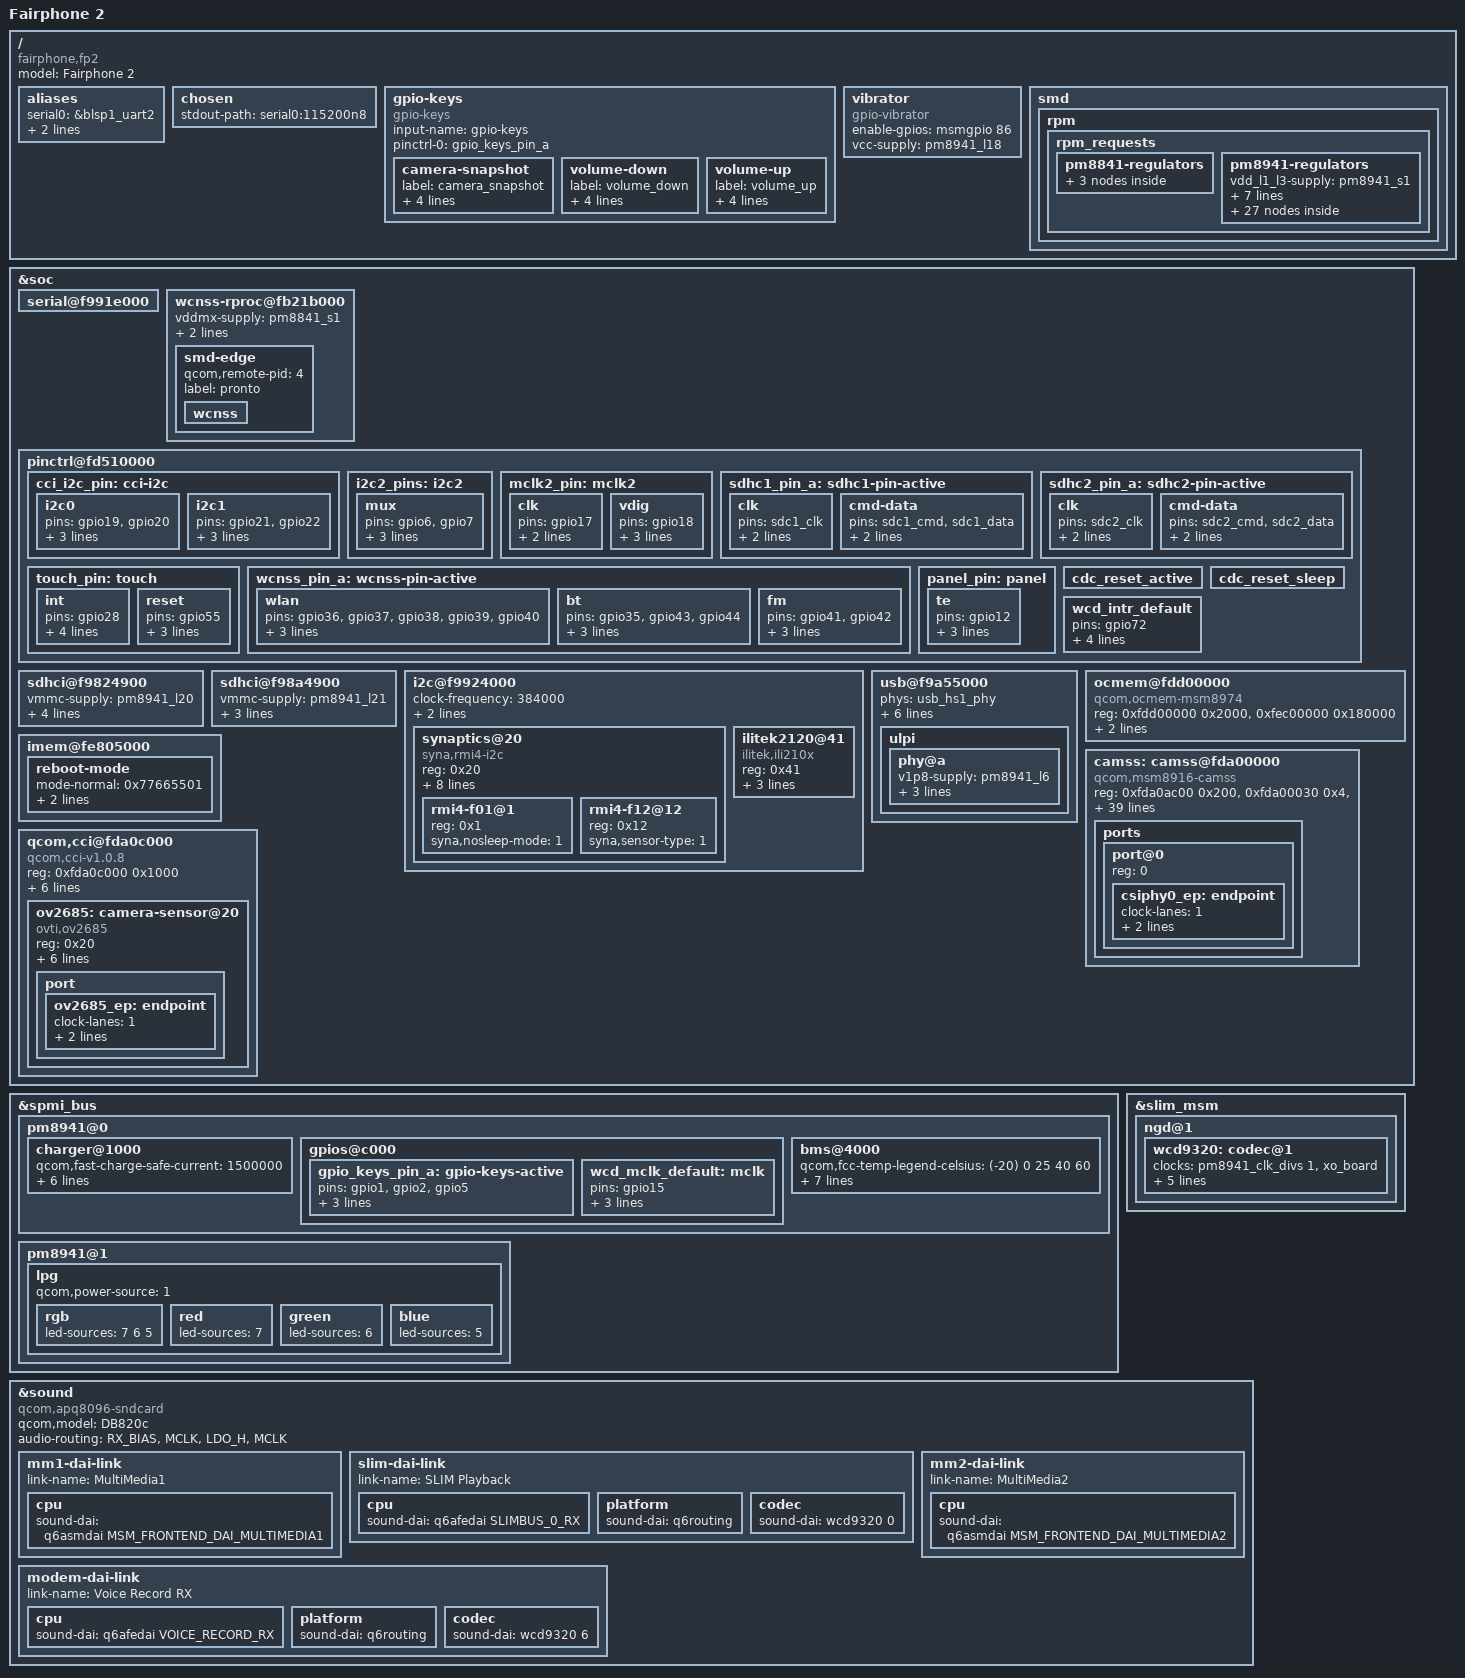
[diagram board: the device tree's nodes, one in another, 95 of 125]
#include "qcom-msm8974pro.dtsi"
#include "qcom-pm8841.dtsi"
#include "qcom-pm8941.dtsi"
#include <dt-bindings/gpio/gpio.h>
#include <dt-bindings/input/input.h>
#include <dt-bindings/pinctrl/qcom,pmic-gpio.h>
#include <dt-bindings/clock/qcom,mmcc-msm8974.h>


/ {
	model = "Fairphone 2";
	compatible = "fairphone,fp2", "qcom,msm8974";

	aliases {
		serial0 = &blsp1_uart2;
		mmc0 = &sdhc_1;
		mmc1 = &sdhc_3;
	};

	chosen {
		stdout-path = "serial0:115200n8";
	};

	gpio-keys {
		compatible = "gpio-keys";
		input-name = "gpio-keys";

		pinctrl-names = "default";
		pinctrl-0 = <&gpio_keys_pin_a>;

		camera-snapshot {
			label = "camera_snapshot";
			gpios = <&pm8941_gpios 1 GPIO_ACTIVE_LOW>;
			linux,code = <KEY_CAMERA>;
			wakeup-source;
			debounce-interval = <15>;
		};

		volume-down {
			label = "volume_down";
			gpios = <&pm8941_gpios 2 GPIO_ACTIVE_LOW>;
			linux,code = <KEY_VOLUMEDOWN>;
			wakeup-source;
			debounce-interval = <15>;
		};

		volume-up {
			label = "volume_up";
			gpios = <&pm8941_gpios 5 GPIO_ACTIVE_LOW>;
			linux,code = <KEY_VOLUMEUP>;
			wakeup-source;
			debounce-interval = <15>;
		};
	};

	vibrator {
		compatible = "gpio-vibrator";
		enable-gpios = <&msmgpio 86 GPIO_ACTIVE_HIGH>;
		vcc-supply = <&pm8941_l18>;
	};

	smd {
		rpm {
			rpm_requests {
				pm8841-regulators {
					s1 {
						regulator-min-microvolt = <675000>;
						regulator-max-microvolt = <1050000>;
					};

					s2 {
						regulator-min-microvolt = <500000>;
						regulator-max-microvolt = <1050000>;
					};

					s3 {
						regulator-min-microvolt = <1050000>;
						regulator-max-microvolt = <1050000>;
					};
				};

				pm8941-regulators {
					vdd_l1_l3-supply = <&pm8941_s1>;
					vdd_l2_lvs1_2_3-supply = <&pm8941_s3>;
					vdd_l4_l11-supply = <&pm8941_s1>;
					vdd_l5_l7-supply = <&pm8941_s2>;
					vdd_l6_l12_l14_l15-supply = <&pm8941_s2>;
					vdd_l9_l10_l17_l22-supply = <&vreg_boost>;
					vdd_l13_l20_l23_l24-supply = <&vreg_boost>;
					vdd_l21-supply = <&vreg_boost>;

					s1 {
						regulator-min-microvolt = <1300000>;
						regulator-max-microvolt = <1300000>;

						regulator-always-on;
						regulator-boot-on;
					};

					s2 {
						regulator-min-microvolt = <2150000>;
						regulator-max-microvolt = <2150000>;

						regulator-boot-on;
					};

					s3 {
						regulator-min-microvolt = <1800000>;
						regulator-max-microvolt = <1800000>;

						regulator-always-on;
						regulator-boot-on;
					};

					l1 {
						regulator-min-microvolt = <1225000>;
						regulator-max-microvolt = <1225000>;

						regulator-always-on;
						regulator-boot-on;
					};

					l2 {
						regulator-min-microvolt = <1200000>;
						regulator-max-microvolt = <1200000>;
					};

					l3 {
						regulator-min-microvolt = <1225000>;
						regulator-max-microvolt = <1225000>;
					};

					l4 {
						regulator-min-microvolt = <1225000>;
						regulator-max-microvolt = <1225000>;
					};

					l5 {
						regulator-min-microvolt = <1800000>;
						regulator-max-microvolt = <1800000>;
					};

					l6 {
						regulator-min-microvolt = <1800000>;
						regulator-max-microvolt = <1800000>;

						regulator-boot-on;
					};

					l7 {
						regulator-min-microvolt = <1800000>;
						regulator-max-microvolt = <1800000>;

						regulator-boot-on;
					};

					l8 {
						regulator-min-microvolt = <1800000>;
						regulator-max-microvolt = <1800000>;
					};

					l9 {
						regulator-min-microvolt = <1800000>;
						regulator-max-microvolt = <2950000>;
					};

					l10 {
						regulator-min-microvolt = <1800000>;
						regulator-max-microvolt = <2950000>;
					};

					l11 {
						regulator-min-microvolt = <1225000>;
						regulator-max-microvolt = <1350000>;
					};

					l12 {
						regulator-min-microvolt = <1800000>;
						regulator-max-microvolt = <1800000>;

						regulator-always-on;
						regulator-boot-on;
					};

					l13 {
						regulator-min-microvolt = <1800000>;
						regulator-max-microvolt = <2950000>;

						regulator-boot-on;
					};

					l14 {
						regulator-min-microvolt = <1800000>;
						regulator-max-microvolt = <1800000>;
					};

					l15 {
						regulator-min-microvolt = <2050000>;
						regulator-max-microvolt = <2050000>;
					};

					l16 {
						regulator-min-microvolt = <2700000>;
						regulator-max-microvolt = <2700000>;
					};

					l17 {
						regulator-min-microvolt = <2850000>;
						regulator-max-microvolt = <2850000>;
					};

					l18 {
						regulator-min-microvolt = <2850000>;
						regulator-max-microvolt = <2850000>;
					};

					l19 {
						regulator-min-microvolt = <2900000>;
						regulator-max-microvolt = <3350000>;
					};

					l20 {
						regulator-min-microvolt = <2950000>;
						regulator-max-microvolt = <2950000>;

						regulator-boot-on;
						regulator-system-load = <200000>;
						regulator-allow-set-load;
					};

					l21 {
						regulator-min-microvolt = <2950000>;
						regulator-max-microvolt = <2950000>;

						regulator-boot-on;
					};

					l22 {
						regulator-min-microvolt = <3000000>;
						regulator-max-microvolt = <3300000>;
					};

					l23 {
						regulator-min-microvolt = <3000000>;
						regulator-max-microvolt = <3000000>;
					};

					l24 {
						regulator-min-microvolt = <3075000>;
						regulator-max-microvolt = <3075000>;

						regulator-boot-on;
					};
				};
			};
		};
	};
};

&soc {
	serial@f991e000 {
		status = "ok";
	};

	wcnss-rproc@fb21b000 {
		status = "ok";

		vddmx-supply = <&pm8841_s1>;
		vddcx-supply = <&pm8841_s2>;

		pinctrl-names = "default";
		pinctrl-0 = <&wcnss_pin_a>;

		smd-edge {
			qcom,remote-pid = <4>;
			label = "pronto";

			wcnss {
				status = "ok";
			};
		};
	};

	pinctrl@fd510000 {
		cci_i2c_pin: cci-i2c {
			i2c0 {
				pins = "gpio19", "gpio20";
				function = "cci_i2c0";

				drive-strength = <2>;
				bias-disable;
			};
			i2c1 {
				pins = "gpio21", "gpio22";
				function = "cci_i2c1";

				drive-strength = <2>;
				bias-disable;
			};
		};

		i2c2_pins: i2c2 {
			mux {
				pins = "gpio6", "gpio7";
				function = "blsp_i2c2";

				drive-strength = <2>;
				bias-disable;
			};
		};

/*
		mclk0_pin: mclk0 {
			clk {
				pins = "gpio15";
				function = "cam_mclk0";
				bias-disable;
				//output-high;
			};
		};
*/

		mclk2_pin: mclk2 {
			clk {
				pins = "gpio17";
				function = "cam_mclk2";
				bias-disable;
			};
			vdig { // FIXME name is weird, v-digital? or reset pin?
				pins = "gpio18";
				function = "gpio";
				drive-strength = <2>;
				bias-disable;
			};
		};

		sdhc1_pin_a: sdhc1-pin-active {
			clk {
				pins = "sdc1_clk";
				drive-strength = <16>;
				bias-disable;
			};

			cmd-data {
				pins = "sdc1_cmd", "sdc1_data";
				drive-strength = <10>;
				bias-pull-up;
			};
		};

		sdhc2_pin_a: sdhc2-pin-active {
			clk {
				pins = "sdc2_clk";
				drive-strength = <10>;
				bias-disable;
			};

			cmd-data {
				pins = "sdc2_cmd", "sdc2_data";
				drive-strength = <6>;
				bias-pull-up;
			};
		};

		touch_pin: touch {
			int {
				pins = "gpio28";
				function = "gpio";

				drive-strength = <2>;
				bias-disable;
				input-enable;
			};

			reset {
				pins = "gpio55";
				function = "gpio";

				drive-strength = <2>;
				bias-pull-up;
			};
		};

		wcnss_pin_a: wcnss-pin-active {
			wlan {
				pins =  "gpio36", "gpio37", "gpio38", "gpio39", "gpio40";
				function = "wlan";

				drive-strength = <6>;
				bias-pull-down;
			};

			bt {
				pins = "gpio35", "gpio43", "gpio44";
				function = "bt";

				drive-strength = <2>;
				bias-pull-down;
			};

			fm {
				pins = "gpio41", "gpio42";
				function = "fm";

				drive-strength = <2>;
				bias-pull-down;
			};
		};

		panel_pin: panel {
			te {
				pins = "gpio12";
				function = "mdp_vsync";

				drive-strength = <2>;
				bias-disable;
			};
		};

		cdc_reset_active: cdc_reset_active {

		};

		cdc_reset_sleep: cdc_reset_sleep {

		};

		wcd_intr_default: wcd_intr_default {
			pins = "gpio72";
			function = "gpio";
			drive-strength = <2>;
			bias-disable;
			input-enable;
		};
	};

	sdhci@f9824900 {
		status = "ok";

		vmmc-supply = <&pm8941_l20>;
		vqmmc-supply = <&pm8941_s3>;

		bus-width = <8>;
		non-removable;

		pinctrl-names = "default";
		pinctrl-0 = <&sdhc1_pin_a>;
	};

	sdhci@f98a4900 {
		status = "ok";

		vmmc-supply = <&pm8941_l21>;
		vqmmc-supply = <&pm8941_l13>;

		bus-width = <4>;

		pinctrl-names = "default";
		pinctrl-0 = <&sdhc2_pin_a>;
	};


	i2c@f9924000 {
		status = "ok";

		clock-frequency = <384000>;
		qcom,src-freq = <19200000>;

		pinctrl-names = "default";
		pinctrl-0 = <&i2c2_pins>;

		synaptics@20 {
			compatible = "syna,rmi4-i2c";
			reg = <0x20>;

			interrupts-extended = <&msmgpio 28 IRQ_TYPE_LEVEL_LOW>;

			#address-cells = <1>;
			#size-cells = <0>;

			vdd-supply = <&pm8941_l22>;
			vio-supply = <&pm8941_s3>;

			pinctrl-names = "default";
			pinctrl-0 = <&touch_pin>;

			syna,nosleep-mode = <2>;
			syna,startup-delay-ms = <160>;
			syna,reset-delay-ms = <100>;

			rmi4-f01@1 {
				reg = <0x1>;
				syna,nosleep-mode = <1>;
			};

			rmi4-f12@12 {
				reg = <0x12>;
				syna,sensor-type = <1>;
			};
		};

		ilitek2120@41 {
			compatible = "ilitek,ili210x";
			reg = <0x41>;
			interrupt-parent = <&msmgpio>;
			interrupts = <28 IRQ_TYPE_EDGE_FALLING>;
			reset-gpios = <&msmgpio 55 GPIO_ACTIVE_LOW>;
		};
	};

	usb@f9a55000 {
		status = "ok";

		phys = <&usb_hs1_phy>;
		phy-select = <&tcsr 0xb000 0>;
		extcon = <&smbb>, <&usb_id>;
		vbus-supply = <&chg_otg>;

		hnp-disable;
		srp-disable;
		adp-disable;

		ulpi {
			phy@a {
				status = "ok";

				v1p8-supply = <&pm8941_l6>;
				v3p3-supply = <&pm8941_l24>;

				extcon = <&smbb>;
				qcom,init-seq = /bits/ 8 <0x1 0x64>;
			};
		};
	};

	ocmem@fdd00000 {
		compatible = "qcom,ocmem-msm8974";
		// "ocmem_ctrl_physical" should be the registers, "ocmem_physical"
		// is (I think) letting CPU read ocmem directly..

		reg = <0xfdd00000 0x2000>,
			<0xfec00000 0x180000>;
		reg-names = "ocmem_ctrl_physical",
			"ocmem_physical";

		clocks = <&rpmcc RPM_SMD_OCMEMGX_CLK>,
			<&mmcc OCMEMCX_OCMEMNOC_CLK>;
		clock-names = "core_clk", "iface_clk";
	};

	/*mdss@fd900000 {
		status = "ok";

		mdp@fd900000 {
			status = "ok";
		};

		dsi@fd922800 {
			status = "ok";

			vdda-supply = <&pm8941_l2>;
			vdd-supply = <&pm8941_l22>;
			vddio-supply = <&pm8941_l12>;

			#address-cells = <1>;
			#size-cells = <0>;

			ports {
				port@1 {
					endpoint {
						remote-endpoint = <&panel_in>;
						data-lanes = <0 1 2 3>;
					};
				};
			};

			panel: panel@0 {
				reg = <0>;
				compatible = "something,s6d6fa1";

				pinctrl-names = "default";
				pinctrl-0 = <&panel_pin>;

				port {
					panel_in: endpoint {
						remote-endpoint = <&dsi0_out>;
					};
				};
			};
		};

		dsi-phy@fd922a00 {
			status = "ok";

			vddio-supply = <&pm8941_l12>;
		};
	};*/

	imem@fe805000 {
		status = "okay";

		reboot-mode {
			mode-normal	= <0x77665501>;
			mode-bootloader	= <0x77665500>;
			mode-recovery	= <0x77665502>;
		};
	};

	camss: camss@fda00000 {
		// missing cpp and cci blocks + msm-cam

		compatible = "qcom,msm8916-camss";
		reg = <0xfda0ac00 0x200>,
			<0xfda00030 0x4>,
			<0xfda0b000 0x200>,
			<0xfda00038 0x4>,
			<0xfda0b400 0x200>,
			<0xfda00040 0x4>,

			<0xfda08000 0x100>,
			<0xfda08400 0x100>,
			<0xfda08800 0x100>,
			<0xfda08c00 0x100>,

			<0xfda0a000 0x800>,
			<0xfda00020 0x10>,
			<0xfda10000 0x1000>,
			<0xfda14000 0x1000>;
		// 0xfda40000 0x200 : vfe_vbif
		reg-names = "csiphy0",
			"csiphy0_clk_mux",
			"csiphy1",
			"csiphy1_clk_mux",
			"csiphy2",
			"csiphy2_clk_mux",
			"csid0",
			"csid1",
			"csid2",
			"csid3",
			"ispif",
			"csi_clk_mux",
			"vfe0",
			"vfe1";
		interrupts = <GIC_SPI 78 0>,
			<GIC_SPI 79 0>,
			<GIC_SPI 80 0>,
			<GIC_SPI 51 0>,
			<GIC_SPI 52 0>,
			<GIC_SPI 53 0>,
			<GIC_SPI 54 0>,
			<GIC_SPI 55 0>,
			<GIC_SPI 57 0>,
			<GIC_SPI 58 0>;
		interrupt-names = "csiphy0",
			"csiphy1",
			"csiphy2",
			"csid0",
			"csid1",
			"csid2",
			"csid3",
			"ispif",
			"vfe0",
			"vfe1";
		power-domains = <&mmcc CAMSS_VFE_GDSC>;
		clocks = <&mmcc CAMSS_TOP_AHB_CLK>,
			<&mmcc CAMSS_ISPIF_AHB_CLK>,
			<&mmcc CAMSS_PHY0_CSI0PHYTIMER_CLK>,
			<&mmcc CAMSS_PHY1_CSI1PHYTIMER_CLK>,
			<&mmcc CAMSS_PHY2_CSI2PHYTIMER_CLK>,

			<&mmcc CAMSS_CSI0_AHB_CLK>, <&mmcc CAMSS_CSI0_CLK>, <&mmcc CAMSS_CSI0PHY_CLK>,
			<&mmcc CAMSS_CSI0PIX_CLK>, <&mmcc CAMSS_CSI0RDI_CLK>,
			<&mmcc CAMSS_CSI1_AHB_CLK>, <&mmcc CAMSS_CSI1_CLK>, <&mmcc CAMSS_CSI1PHY_CLK>,
			<&mmcc CAMSS_CSI1PIX_CLK>, <&mmcc CAMSS_CSI1RDI_CLK>,
			<&mmcc CAMSS_CSI2_AHB_CLK>, <&mmcc CAMSS_CSI2_CLK>, <&mmcc CAMSS_CSI2PHY_CLK>,
			<&mmcc CAMSS_CSI2PIX_CLK>, <&mmcc CAMSS_CSI2RDI_CLK>,
			<&mmcc CAMSS_CSI3_AHB_CLK>, <&mmcc CAMSS_CSI3_CLK>, <&mmcc CAMSS_CSI3PHY_CLK>,
			<&mmcc CAMSS_CSI3PIX_CLK>, <&mmcc CAMSS_CSI3RDI_CLK>,

			// <&gcc GCC_CAMSS_AHB_CLK>,

			<&mmcc CAMSS_VFE_VFE0_CLK>,
			<&mmcc CAMSS_VFE_VFE1_CLK>,
			<&mmcc CAMSS_CSI_VFE0_CLK>,
			<&mmcc CAMSS_CSI_VFE1_CLK>,
			<&mmcc CAMSS_VFE_VFE_AHB_CLK>,
			<&mmcc CAMSS_VFE_VFE_AXI_CLK>;
		// CAMSS_VFE_VFE_OCMEMNOC_CLK
                clock-names = "top_ahb",
                        "ispif_ahb",
                        "csiphy0_timer",
                        "csiphy1_timer",
                        "csiphy2_timer",
                        "csi0_ahb", "csi0", "csi0_phy", "csi0_pix", "csi0_rdi",
                        "csi1_ahb", "csi1", "csi1_phy", "csi1_pix", "csi1_rdi",
                        "csi2_ahb", "csi2", "csi2_phy", "csi2_pix", "csi2_rdi",
                        "csi3_ahb", "csi3", "csi3_phy", "csi3_pix", "csi3_rdi",
                        // "camss_ahb",
                        "vfe0",
                        "vfe1",
                        "csi_vfe0",
                        "csi_vfe1",
                        "iface",
                        "bus";
		vdda-supply = <&pm8941_l12>;
		// iommus = <...>;
		ports {
			#address-cells = <1>;
			#size-cells = <0>;
			port@0 {
				reg = <0>;
				csiphy0_ep: endpoint {
					clock-lanes = <1>;
					data-lanes = <0 2 3 4>;
					remote-endpoint = <&ov2685_ep>;
				};
			};
		};
	};

	qcom,cci@fda0c000 {
		compatible = "qcom,cci-v1.0.8";
		#address-cells = <1>;
		#size-cells = <0>;
		reg = <0xfda0c000 0x1000>;
		reg-names = "cci";
		interrupts = <GIC_SPI 50 IRQ_TYPE_EDGE_RISING>;
		interrupt-names = "cci";
		clocks = <&mmcc CAMSS_TOP_AHB_CLK>,
			<&mmcc CAMSS_CCI_CCI_AHB_CLK>,
			<&mmcc CAMSS_CCI_CCI_CLK>;
			// <&gcc GCC_CAMSS_AHB_CLK>;
		clock-names = "camss_top_ahb",
			"cci_ahb",
			"cci";
			// "camss_ahb";
		pinctrl-names = "default";
		pinctrl-0 = <&cci_i2c_pin>;

		clock-frequency = <400000>;

		ov2685: camera-sensor@20 {
			compatible = "ovti,ov2685";
			reg = <0x20>;

			clocks = <&mmcc CAMSS_MCLK2_CLK>;
			clock-names = "xvclk";

			avdd-supply = <&pm8941_l22>;
			dovdd-supply = <&pm8941_lvs3>;
			dvdd-supply = <&pm8941_l3>;
			reset-gpios = <&msmgpio 18 GPIO_ACTIVE_HIGH>;

			// Uses csid & csiphy instance nr. 2 (0-index-based)

			pinctrl-names = "default";
			pinctrl-0 = <&mclk2_pin>;

			port {
				ov2685_ep: endpoint {
					clock-lanes = <1>;
					data-lanes = <0 2 3 4>;
					remote-endpoint = <&csiphy0_ep>;
					//data-lanes = <1>;
				};
			};
		};

		// missing:
		// rear cam
		// front cam
		// actuator
		// eeprom <- what is it for ?
	};
};

&spmi_bus {
	pm8941@0 {
		charger@1000 {
			qcom,fast-charge-safe-current = <1500000>; // confirmed
			qcom,fast-charge-current-limit = <1500000>; // confirmed
			//qcom,dc-current-limit = <>; // 1800000 is used on other msm8974 devices
			qcom,fast-charge-safe-voltage = <4380000>; // confirmed
			qcom,fast-charge-high-threshold-voltage = <4350000>; // confirmed
			//qcom,fast-charge-low-threshold-voltage = <>; // not present downstream
			qcom,auto-recharge-threshold-voltage = <4250000>; // confirmed
			qcom,minimum-input-voltage = <4450000>; // confirmed
		};

		gpios@c000 {
			gpio_keys_pin_a: gpio-keys-active {
				pins = "gpio1", "gpio2", "gpio5";
				function = "normal";

				bias-pull-up;
				power-source = <PM8941_GPIO_S3>;
			};

			wcd_mclk_default: mclk {
				pins = "gpio15";
				function = "func1";

				output-high;
				power-source = <PM8941_GPIO_S3>;
			};
		};

		bms@4000 {
			status = "ok";

			qcom,fcc-temp-legend-celsius = /bits/ 8 <(-20) 0 25 40 60>;
			qcom,fcc-lut-microamp-hours = <2361000 2396000 2404000 2403000 2394000>;

			qcom,ocv-temp-legend-celsius = /bits/ 8 <(-20) 0 25 40 60>;
			qcom,ocv-capacity-legend = /bits/ 8 <100 95 90 85 80 75
							     70 65 60 55 50 45
							     40 35 30 25 20 16
							     13 11 10 9 8 7 6
							     5 4 3 2 1 0>;
			qcom,ocv-lut-microvolt = <4334000 4332000 4327000 4324000 4316000
						  4184000 4234000 4249000 4250000 4246000
						  4094000 4162000 4186000 4188000 4186000
						  4020000 4100000 4128000 4132000 4132000
						  3948000 4051000 4080000 4086000 4087000
						  3896000 3986000 4038000 4044000 4044000
						  3852000 3942000 3996000 4000000 3999000
						  3819000 3901000 3948000 3956000 3956000
						  3798000 3864000 3892000 3898000 3898000
						  3782000 3833000 3858000 3862000 3863000
						  3764000 3804000 3830000 3834000 3836000
						  3744000 3782000 3807000 3811000 3812000
						  3722000 3765000 3786000 3790000 3791000
						  3698000 3747000 3768000 3768000 3760000
						  3668000 3723000 3748000 3744000 3734000
						  3630000 3694000 3718000 3714000 3703000
						  3577000 3674000 3684000 3680000 3672000
						  3520000 3654000 3672000 3671000 3662000
						  3466000 3629000 3656000 3652000 3637000
						  3418000 3599000 3618000 3616000 3600000
						  3392000 3578000 3594000 3592000 3576000
						  3359000 3546000 3564000 3562000 3546000
						  3322000 3510000 3530000 3529000 3514000
						  3279000 3466000 3494000 3495000 3484000
						  3233000 3419000 3458000 3462000 3456000
						  3186000 3369000 3424000 3428000 3423000
						  3142000 3324000 3384000 3386000 3380000
						  3104000 3270000 3331000 3334000 3326000
						  3072000 3203000 3260000 3260000 3251000
						  3040000 3120000 3160000 3155000 3138000
						  3000000 3012000 3000000 3000000 3005000>;
		};
	};

	pm8941@1 {
		lpg {
			status = "okay";

			qcom,power-source = <1>;

			rgb {
				led-sources = <7 6 5>;
			};

			red {
				led-sources = <7>;
			};
			green {
				led-sources = <6>;
			};
			blue {
				led-sources = <5>;
			};
		};
	};
};


&slim_msm {
	ngd@1 {
		wcd9320: codec@1 {
			clock-names = "mclk", "slimbus";
			clocks = <&pm8941_clk_divs 1>,
				 <&xo_board>; // XXX
			qcom,mbhc-vthreshold = <75 150 237 500 500 500 500 500>; // XXX

			pinctrl-0 = <&cdc_reset_active &wcd_intr_default &wcd_mclk_default>;
			pinctrl-1 = <&cdc_reset_sleep>;
			pinctrl-names = "default", "sleep";
		};
	};
};

&sound {
	compatible = "qcom,apq8096-sndcard";
	qcom,model = "DB820c";
	audio-routing =
		"RX_BIAS", "MCLK",
		"LDO_H", "MCLK";
#if 0
		"AMIC1", "MIC BIAS1 External",
		"MIC BIAS1 External", "Handset Mic",
		"AMIC2", "MIC BIAS2 External",
		"MIC BIAS2 External", "Headset Mic",
		"AMIC3", "MIC BIAS3 External",
		"MIC BIAS3 External", "Handset SubMic",
		"DMIC1", "MIC BIAS1 External",
		"MIC BIAS1 External", "Digital Mic1",
		"DMIC2", "MIC BIAS1 External",
		"MIC BIAS1 External", "Digital Mic2",
		"DMIC3", "MIC BIAS3 External",
		"MIC BIAS3 External", "Digital Mic3",
		"DMIC4", "MIC BIAS3 External",
		"MIC BIAS3 External", "Digital Mic4",
		"DMIC5", "MIC BIAS4 External",
		"MIC BIAS4 External", "Digital Mic5",
		"DMIC6", "MIC BIAS4 External",
		"MIC BIAS4 External", "Digital Mic6";
#endif

	mm1-dai-link {
		link-name = "MultiMedia1";
		cpu {
			sound-dai = <&q6asmdai  MSM_FRONTEND_DAI_MULTIMEDIA1>;
		};
	};

	slim-dai-link {
		link-name = "SLIM Playback";
		cpu {
			sound-dai = <&q6afedai SLIMBUS_0_RX>;
		};

		platform {
			sound-dai = <&q6routing>;
		};

		codec {
			sound-dai = <&wcd9320 0>;
		};
	};

	// hack
	mm2-dai-link {
		link-name = "MultiMedia2";
		cpu {
			sound-dai = <&q6asmdai  MSM_FRONTEND_DAI_MULTIMEDIA2>;
		};
	};

	modem-dai-link {
		link-name = "Voice Record RX";
		cpu {
			sound-dai = <&q6afedai VOICE_RECORD_RX>;
		};

		platform {
			sound-dai = <&q6routing>;
		};

		codec {
			sound-dai = <&wcd9320 6>;
		};
	};
};
